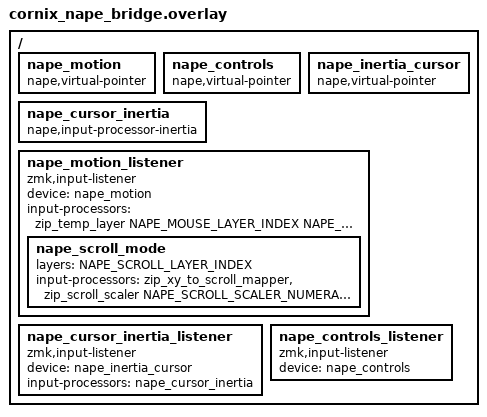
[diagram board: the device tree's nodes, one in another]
#include <input/processors.dtsi>
#include "nape_layer_index.h"

/ {
    nape_motion: nape_motion {
        compatible = "nape,virtual-pointer";
        status = "okay";
    };

    nape_controls: nape_controls {
        compatible = "nape,virtual-pointer";
        status = "okay";
    };

    nape_inertia_cursor: nape_inertia_cursor {
        compatible = "nape,virtual-pointer";
        status = "okay";
    };

    nape_cursor_inertia: nape_cursor_inertia {
        compatible = "nape,input-processor-inertia";
        #input-processor-cells = <0>;
        status = "okay";
    };

    nape_motion_listener {
        compatible = "zmk,input-listener";
        device = <&nape_motion>;
        input-processors = <&zip_temp_layer NAPE_MOUSE_LAYER_INDEX NAPE_MOUSE_LAYER_TIMEOUT_MS>;

        nape_scroll_mode {
            layers = <NAPE_SCROLL_LAYER_INDEX>;
            input-processors =
                <&zip_xy_to_scroll_mapper>,
                <&zip_scroll_scaler NAPE_SCROLL_SCALER_NUMERATOR NAPE_SCROLL_SCALER_DENOMINATOR>;
        };
    };

    nape_cursor_inertia_listener {
        compatible = "zmk,input-listener";
        device = <&nape_inertia_cursor>;
        input-processors = <&nape_cursor_inertia>;
    };

    nape_controls_listener {
        compatible = "zmk,input-listener";
        device = <&nape_controls>;
    };
};
